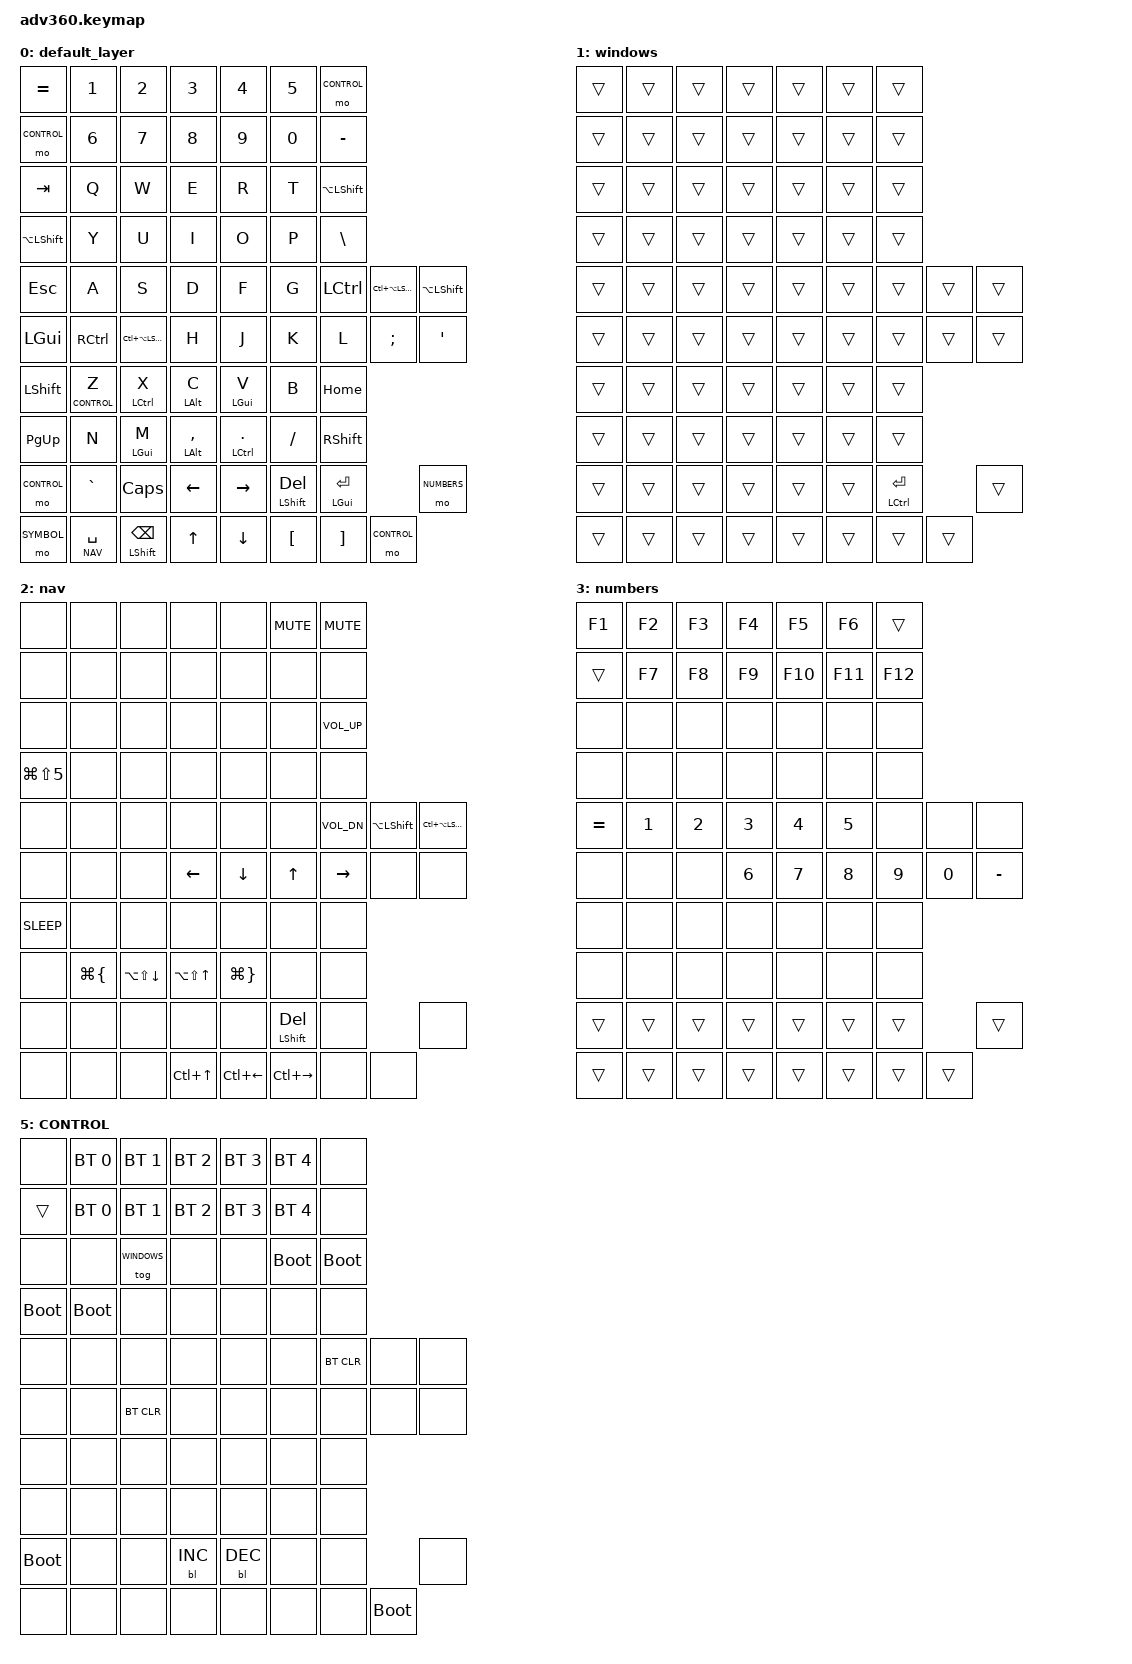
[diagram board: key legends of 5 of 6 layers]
/*
 * Copyright (c) 2020 The ZMK Contributors
 *
 * SPDX-License-Identifier: MIT
 */


/* THIS FILE WAS GENERATED!
 *
 * This file was generated automatically. You may or may not want to
 * edit it directly.
 */

#include <behaviors.dtsi>
#include <dt-bindings/zmk/keys.h>
#include <dt-bindings/zmk/bt.h>
#include <dt-bindings/zmk/rgb.h>
#include <dt-bindings/zmk/ext_power.h>
#include <dt-bindings/zmk/backlight.h>

#define DEFAULT 0
#define WINDOWS 1
#define NAV   2
#define NUMBERS   3
#define SYMBOL   4
#define CONTROL   5


/ {
    combos {
        compatible = "zmk,combos";
        combo_esc {
            timeout-ms = <50>;
            key-positions = <16 17>;
            bindings = <&gresc>;
        };
		combo_tab {
            timeout-ms = <50>;
            key-positions = <30 31>;
            bindings = <&kp TAB>;
        };
		combo_quote {
            timeout-ms = <50>;
            key-positions = <43 44>;
            bindings = <&kp SQT>;
        };
		combo_cmdenter {
            timeout-ms = <80>;
            key-positions = <49 54>;
            bindings = <&kp LG(RET)>;
        };
    };
};


/ {
	behaviors {
			hm: homerow_mods {
					compatible = "zmk,behavior-hold-tap";
					label = "HOMEROW_MODS";
					#binding-cells = <2>;
					tapping-term-ms = <200>;
					quick_tap_ms = <100>;
					flavor = "tap-preferred";
					bindings = <&kp>, <&kp>;
			};
			tm: thumb_mods {
					compatible = "zmk,behavior-hold-tap";
					label = "THUMB_MODS";
					#binding-cells = <2>;
					tapping-term-ms = <150>;
					quick_tap_ms = <75>;
					flavor = "tap-preferred";
					bindings = <&kp>, <&kp>;
			};
			gresc: grave_escape {
			    compatible = "zmk,behavior-mod-morph";
			    label = "GRAVE_ESCAPE";
			    #binding-cells = <0>;
			    bindings = <&kp ESC>, <&kp GRAVE>;
			    mods = <(MOD_LGUI|MOD_LSFT|MOD_RGUI|MOD_RSFT)>;
			    keep-mods = <(MOD_LGUI|MOD_RGUI)>;
			};
		};
};

/ {
    keymap {
        compatible = "zmk,keymap";


        default_layer {
            bindings = <
// Row 1 Left - 7
&kp EQUAL &kp N1 &kp N2 &kp N3 &kp N4 &kp N5 &mo CONTROL
// Row 1 Right - 7 
&mo CONTROL &kp N6 &kp N7 &kp N8 &kp N9 &kp N0 &kp MINUS
// Row 2 Left - 7
&kp TAB &kp Q &kp W &kp E &kp R &kp T &kp LA(LSHFT)
// Row 2 Right - 7
&kp LA(LSHFT) &kp Y &kp U &kp I &kp O &kp P &kp BSLH
// Row 3 Left - 9
&kp ESC &kp A &kp S &kp D &kp F &kp G &kp LCTRL &kp LC(LA(LSHFT)) &kp LA(LSHFT)   
// Row 3 Right - 9
&kp LGUI &kp RCTRL  &kp LC(LA(LSHFT)) &kp H &kp J &kp K &kp L &kp SEMI &kp SQT
// Row 4 Left - 7
&kp LSHFT &lt CONTROL Z &hm LCTRL X &hm LALT C &hm LGUI V &kp B  &kp HOME
// Row 4 Right - 7
&kp PG_UP &kp N &hm LGUI M &hm LALT COMMA &hm LCTRL DOT &kp FSLH &kp RSHFT
// Row 5 Left - 8
&mo CONTROL &kp GRAVE &kp CAPS &kp LEFT &kp RIGHT &tm LSHFT DEL &tm LGUI RET &mo NUMBERS
// Row 5 Right - 8
&mo SYMBOL &lt NAV SPACE &tm LSHFT BSPC &kp UP &kp DOWN &kp LBKT &kp RBKT &mo CONTROL
            >;
        };

        windows {
            bindings = <
// Row 1 Left - 7
&trans &trans &trans &trans &trans &trans &trans
// Row 1 Right - 7
&trans &trans &trans &trans &trans &trans &trans
// Row 2 Left - 7
&trans &trans &trans &trans &trans &trans &trans
// Row 2 Right - 7
&trans &trans &trans &trans &trans &trans &trans
// Row 3 Left - 9
&trans &trans &trans &trans &trans &trans &trans &trans &trans
// Row 3 Right - 9
&trans &trans &trans &trans &trans &trans &trans &trans &trans
// Row 4 Left - 7
&trans &trans &trans &trans &trans &trans &trans
// Row 4 Right - 
&trans &trans &trans &trans &trans &trans &trans
// Row 5 Left - 8
&trans &trans &trans &trans &trans &trans &hm LCTRL RET &trans
// Row 5 Right - 8
&trans &trans &trans &trans &trans &trans &trans &trans
            >;
        };

         nav {
            bindings = <
// Row 1 Left - 7
&none &none &none &none &none &kp C_MUTE &kp K_MUTE
// Row 1 Right - 7
&none &none &none &none &none &none &none
// Row 2 Left - 7
&none &none &none &none &none &none &kp C_VOL_UP
// Row 2 Right - 7
&kp LG(LS(N5)) &none &none &none &none &none &none
// Row 3 Left - 9
&none &none &none &none &none &none &kp C_VOL_DN &kp LA(LSHFT) &kp LC(LA(LSHFT))
// Row 3 Right - 9
&none &none &none &kp LEFT &kp DOWN &kp UP &kp RIGHT &none &none
// Row 4 Left - 7
&kp C_SLEEP &none &none &none &none &none &none
// Row 4 Right - 7
&none &kp LG(LBRC) &kp LA(LS(DOWN)) &kp LA(LS(UP)) &kp LG(RBRC) &none &none
// Row 5 Left - 8
&none &none &none &none &none &tm LSHFT DEL &none &none
// Row 5 Right - 8
&none &none &none &kp LC(UP) &kp LC(LEFT) &kp LC(RIGHT) &none &none
            >;
        };


        numbers {
            bindings = <
// Row 1 Left - 7
&kp F1 &kp F2 &kp F3 &kp F4 &kp F5 &kp F6 &trans
// Row 1 Right - 7
&trans &kp F7 &kp F8 &kp F9 &kp F10 &kp F11 &kp F12
// Row 2 Left - 7
&none &none &none &none &none &none &none
// Row 2 Right - 7
&none &none &none &none &none &none &none
// Row 3 Left - 9
&kp EQUAL &kp N1 &kp N2 &kp N3 &kp N4 &kp N5 &none &none &none 
// Row 3 Right - 9
&none &none &none &kp N6 &kp N7 &kp N8 &kp N9 &kp N0 &kp MINUS
// Row 4 Left - 7
&none &none &none &none &none &none &none
// Row 4 Right - 7
&none &none &none &none &none &none &none
// Row 5 Left - 8
&trans &trans &trans &trans &trans &trans &trans &trans
// Row 5 Right - 8
&trans &trans &trans &trans &trans &trans &trans &trans 
            >;
        };

       symbol {
            bindings = <
// Row 1 Left - 7
&none &none &none &none &none &none &none
// Row 1 Right - 7
&none &none &none &none &none &none &none
// Row 2 Left - 7
&none &none &none &none &none &none &none
// Row 2 Right - 7
&none  &kp GRAVE &kp EQUAL &kp LBRC &kp RBRC &kp PIPE &kp BSLH
// Row 3 Left - 9
&none &none &none &none &none &none &none &none &none
// Row 3 Right - 9
&none &none &none &kp LBKT &kp RBKT &kp LPAR &kp RPAR &kp MINUS 
// Row 4 Left - 7
&none &none &none &none &none &none &none
// Row 4 Right - 7
&none &kp PLUS &kp EQUAL &kp LT &kp GT &kp FSLH  &none
// Row 5 Left - 8
&none &none &none &none &none &none &none &none
// Row 5 Right - 8
&none &none &none &none &none &none &none &none
            >;
        };


        CONTROL {
            bindings = <
// Row 1 Left - 7
&none &bt BT_SEL 0 &bt BT_SEL 1 &bt BT_SEL 2 &bt BT_SEL 3 &bt BT_SEL 4 &none
// Row 1 Right - 7
&trans &bt BT_SEL 0 &bt BT_SEL 1 &bt BT_SEL 2 &bt BT_SEL 3 &bt BT_SEL 4 &none
// Row 2 Left - 7
&none &none &tog WINDOWS &none &none &bootloader &bootloader
// Row 2 Right - 7
&bootloader &bootloader &none &none &none &none &none
// Row 3 Left - 9
&none &none &none &none &none &none &bt BT_CLR &none &none
// Row 3 Right - 9
&none &none &bt BT_CLR &none &none &none &none &none &none
// Row 4 Left - 7
&none &none &none &none &none &none &none
// Row 4 Right - 7
&none &none &none &none &none &none &none
// Row 5 Left - 8
&bootloader &none &none &bl BL_INC  &bl BL_DEC &none &none &none
// Row 5 Right - 8
&none &none &none &none &none &none &none &bootloader
            >;
        };

    };
};
